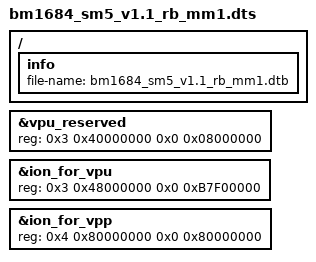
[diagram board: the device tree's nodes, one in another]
#include "bm1684_sm5_v1.1_rb.dts"

/ {
	info {
		file-name = "bm1684_sm5_v1.1_rb_mm1.dtb";
	};
};

&vpu_reserved {
	reg = <0x3 0x40000000 0x0 0x08000000>; // 128M, for VPU firmware
};

&ion_for_vpu {
	/* need to reserve 1M of high address space */
	reg = <0x3 0x48000000 0x0 0xB7F00000>; // 2.875G - 1M, for VPU
};

&ion_for_vpp {
	reg = <0x4 0x80000000 0x0 0x80000000>; // 2G, for VPP/JPU
};
